# M46B register map
File version: 2.0.2.2
Registers are 32-bit, read-write, reset 0x0 unless marked. A register's access mark holds for its fields unless they carry their own. Offsets are from the block's base; [hi:lo] are bit positions; {n}, {i} and the like mark numbered series.

## SNFC — SNFC (SLC NAND Flash Controller)
Base 0x4005C400
0x00 ENC — SNFC Enable Control Register
  [0] EN
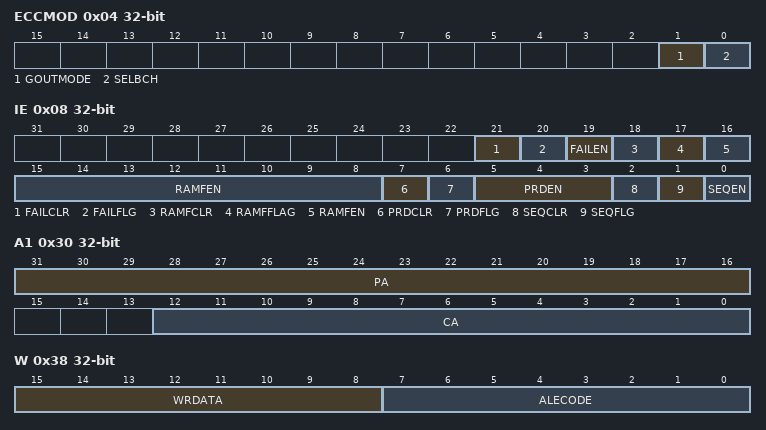
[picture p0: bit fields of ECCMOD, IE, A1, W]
0x04 ECCMOD — SNFC Ecc Mode Register
  [1] GOUTMODE, [0] SELBCH
0x08 IE — SNFC Interrupt Enable Register
  [21] FAILCLR, [20] FAILFLG ro, [19] FAILEN, [18] RAMFCLR, [17] RAMFFLAG ro, [16:8] RAMFEN, [7] PRDCLR, [6] PRDFLG ro, [5:3] PRDEN, [2] SEQCLR, [1] SEQFLG ro, [0] SEQEN
0x10 PS — SNFC Page Size Register
  [12:0] CA
0x14 PRCS — SNFC Page Read Column Status Register
  [12:0] CAST
0x18 S — SNFC Sector Register
  [3:0] SEC
0x1C SS — SNFC Sector Status Register
  [3:0] SECST
0x20 DIC — SNFC Decode Input Count Register
  [9:0] DECIN
0x24 DOC — SNFC Decode Output Count Register
  [9:0] DECOUT
0x28 EIC — SNFC Encode Input Count Register
  [9:0] ENCIN
0x30 A1 — SNFC Address Register 1
  [31:16] PA, [12:0] CA
0x34 A2 — SNFC Address Register 2
  [1:0] PA
0x38 W — SNFC Write Register
  [15:8] WRDATA ro, [7:0] ALECODE
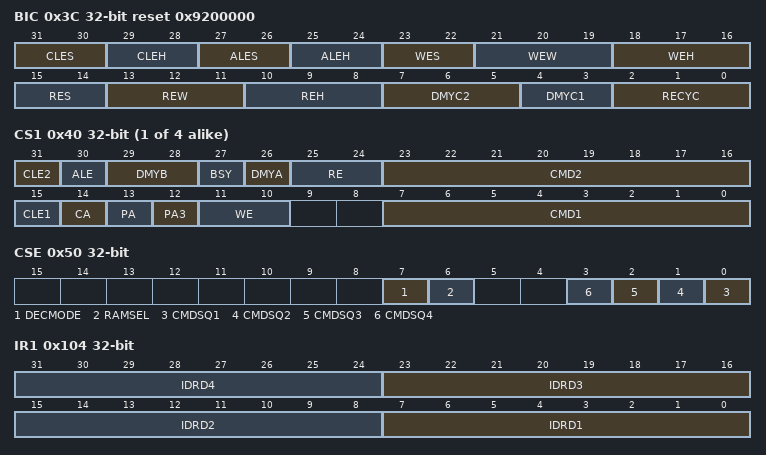
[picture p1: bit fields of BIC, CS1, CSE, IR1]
0x3C BIC reset 0x9200000 — SNFC Bus Interface Control Register
  [31:30] CLES, [29:28] CLEH, [27:26] ALES ro, [25:24] ALEH, [23:22] WES, [21:19] WEW ro, [18:16] WEH, [15:14] RES, [13:11] REW ro, [10:8] REH, [7:5] DMYC2, [4:3] DMYC1 ro, [2:0] RECYC
{0x3C+4i} CS{i} (i=1..4) — SNFC Command Sequence Register {i}
  [31] CLE2, [30] ALE, [29:28] DMYB, [27] BSY, [26] DMYA, [25:24] RE, [23:16] CMD2, [15] CLE1, [14] CA, [13] PA, [12] PA3, [11:10] WE, [7:0] CMD1
0x50 CSE — SNFC Command Sequence Enable Register
  [7] DECMODE, [6] RAMSEL, [n-1] CMDSQ{n} (n=1..4)
0x100 PRDB ro — SNFC Page Read Buffer Registerer
  [31:0] PRDBUF
0x104 IR1 ro — SNFC Id Read Register 1
  [8n-1:8n-8] IDRD{n} (n=1..4)
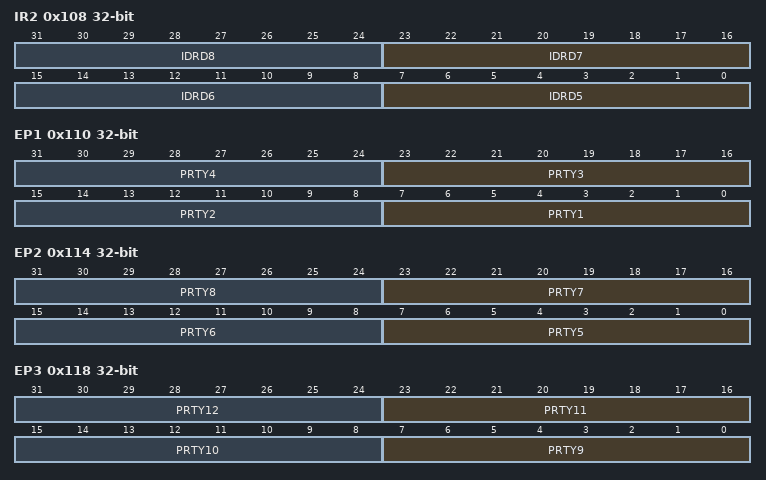
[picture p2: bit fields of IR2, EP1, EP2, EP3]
0x108 IR2 ro — SNFC Id Read Register 2
  [8n-33:8n-40] IDRD{n} (n=5..8)
0x110 EP1 ro — SNFC Ecc Parity Register 1
  [8n-1:8n-8] PRTY{n} (n=1..4)
0x114 EP2 ro — SNFC Ecc Parity Register 2
  [8n-33:8n-40] PRTY{n} (n=5..8)
0x118 EP3 ro — SNFC Ecc Parity Register 3
  [8n-65:8n-72] PRTY{n} (n=9..12)
0x11C EP4 ro — SNFC Ecc Parity Register 4
  [7:0] PRTY13
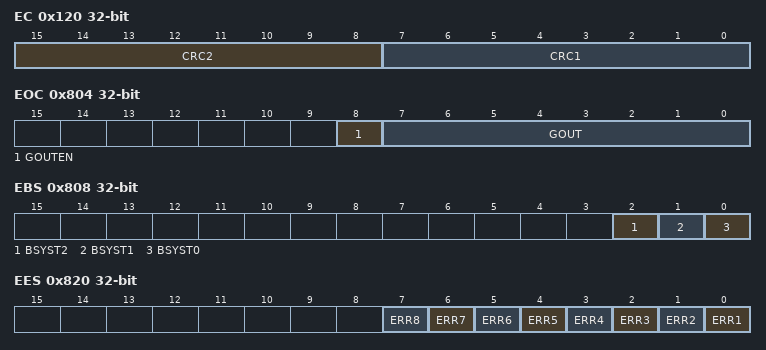
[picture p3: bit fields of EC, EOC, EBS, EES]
0x120 EC ro — SNFC Ecc Crc Register
  [15:8] CRC2, [7:0] CRC1
0x400 EWRB — SNFC Ecc Write Buffer Register
  [31:0] GIBUF
0x800 CDRB ro — SNFC Correction Data Read Buffer Register
  [31:0] RDBUF
0x804 EOC ro — SNFC Ecc Output Control Register
  [8] GOUTEN rw, [7:0] GOUT
0x808 EBS ro — SNFC Ecc Busy Status Register
  [2] BSYST2, [1] BSYST1, [0] BSYST0
0x820 EES ro — SNFC Ecc Error Status Register
  [n-1] ERR{n} (n=1..8)
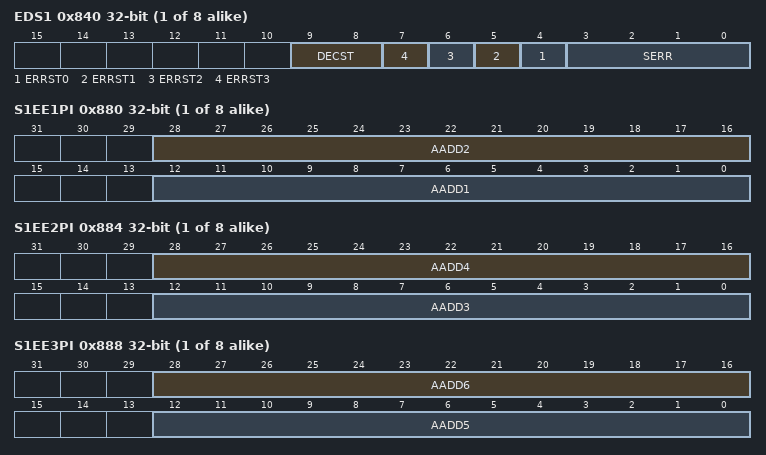
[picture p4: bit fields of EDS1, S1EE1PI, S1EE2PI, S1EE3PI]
{0x83C+4i} EDS{i} ro (i=1..8) — SNFC Ecc Decode State Register {i}
  [9:8] DECST, [n+4] ERRST{n} (n=0..3), [3:0] SERR
{0x870+0x10*i} S{i}EE1PI ro (i=1..8) — SNFC Sector {i} Ecc Error 1 Positional Information Register
  [28:16] AADD2, [12:0] AADD1
{0x874+0x10*i} S{i}EE2PI ro (i=1..8) — SNFC Sector {i} Ecc Error 2 Positional Information Register
  [28:16] AADD4, [12:0] AADD3
{0x878+0x10*i} S{i}EE3PI ro (i=1..8) — SNFC Sector {i} Ecc Error 3 Positional Information Register
  [28:16] AADD6, [12:0] AADD5
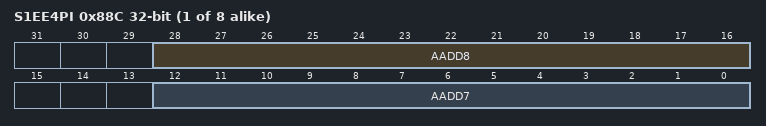
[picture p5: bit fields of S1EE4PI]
{0x87C+0x10*i} S{i}EE4PI ro (i=1..8) — SNFC Sector {i} Ecc Error 4 Positional Information Register
  [28:16] AADD8, [12:0] AADD7

## DMAIF — DMA Interrupt Flag
Base 0x4005F000
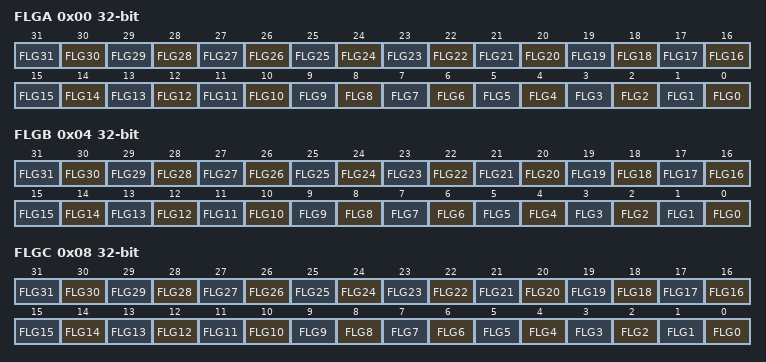
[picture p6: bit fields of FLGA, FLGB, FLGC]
0x00 FLGA ro — DMA Flag Register A
  [n] FLG{n} (n=0..31)
0x04 FLGB ro — DMA Flag Register B
  [n] FLG{n} (n=0..31)
0x08 FLGC ro — DMA Flag Register C
  [n] FLG{n} (n=0..31)

## ADILV — ADC infterface Register
Base 0x40066000
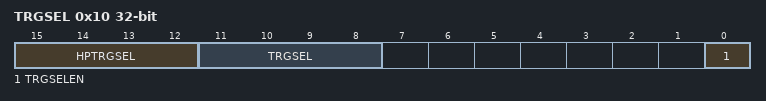
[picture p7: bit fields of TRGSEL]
0x10 TRGSEL — Trigger Selection Register
  [15:12] HPTRGSEL, [11:8] TRGSEL, [0] TRGSELEN

## I2C0 — I2C Bus Interface (I2C)
Base 0x400A0000
Same registers: I2C1 0x400A1000, I2C2 0x400A2000
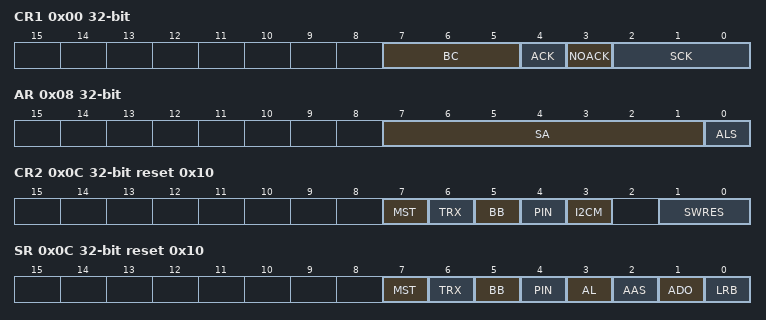
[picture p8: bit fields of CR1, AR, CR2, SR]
0x00 CR1 — I2C Control Register 1
  [7:5] BC, [4] ACK, [3] NOACK, [2:0] SCK
0x04 DBR — Data Buffer Register
  [7:0] DB
0x08 AR — Bus address Register
  [7:1] SA, [0] ALS
0x0C CR2 wo reset 0x10 — Control Register 1
  [7] MST, [6] TRX, [5] BB, [4] PIN, [3] I2CM, [1:0] SWRES
0x0C SR ro reset 0x10 — Status Register
  [7] MST, [6] TRX, [5] BB, [4] PIN, [3] AL, [2] AAS, [1] ADO, [0] LRB
0x10 PRS — Prescaler clcok setting Register
  [4:0] PRSCK
0x14 IE — Interrupt Enable Register
  [0] IE
0x18 IR — Interrupt Register
  [0] ISIC
